# iorx65n register map
Registers are 8-bit, access not given, no defined reset value unless marked. A register's access mark holds for its fields unless they carry their own. Addresses are absolute; registers are grouped by the start of their names; [hi:lo] are bit positions; {n}, {i} and the like mark numbered series; 'fields as' and 'values as' point back to an identical list.

## SFR (part 2 of 7)
0x80000 SYSTEM 16-bit
  [0] MDMONR.MD
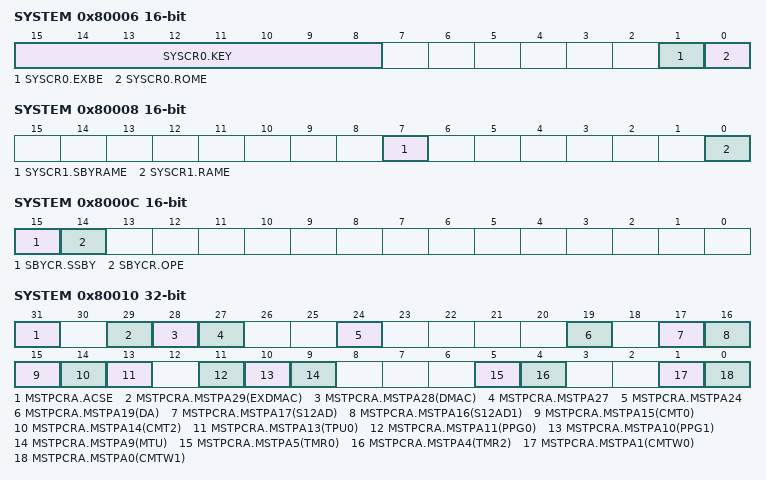
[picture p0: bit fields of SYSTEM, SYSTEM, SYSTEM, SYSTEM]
0x80006 SYSTEM 16-bit
  [15:8] SYSCR0.KEY, [1] SYSCR0.EXBE, [0] SYSCR0.ROME
0x80008 SYSTEM 16-bit
  [7] SYSCR1.SBYRAME, [0] SYSCR1.RAME
0x8000C SYSTEM 16-bit
  [15] SBYCR.SSBY, [14] SBYCR.OPE
0x80010 SYSTEM 32-bit
  [31] MSTPCRA.ACSE, [29] MSTPCRA.MSTPA29(EXDMAC), [28] MSTPCRA.MSTPA28(DMAC), [27] MSTPCRA.MSTPA27, [24] MSTPCRA.MSTPA24, [19] MSTPCRA.MSTPA19(DA), [17] MSTPCRA.MSTPA17(S12AD), [16] MSTPCRA.MSTPA16(S12AD1), [15] MSTPCRA.MSTPA15(CMT0), [14] MSTPCRA.MSTPA14(CMT2), [13] MSTPCRA.MSTPA13(TPU0), [11] MSTPCRA.MSTPA11(PPG0), [10] MSTPCRA.MSTPA10(PPG1), [9] MSTPCRA.MSTPA9(MTU), [5] MSTPCRA.MSTPA5(TMR0), [4] MSTPCRA.MSTPA4(TMR2), [1] MSTPCRA.MSTPA1(CMTW0), [0] MSTPCRA.MSTPA0(CMTW1)
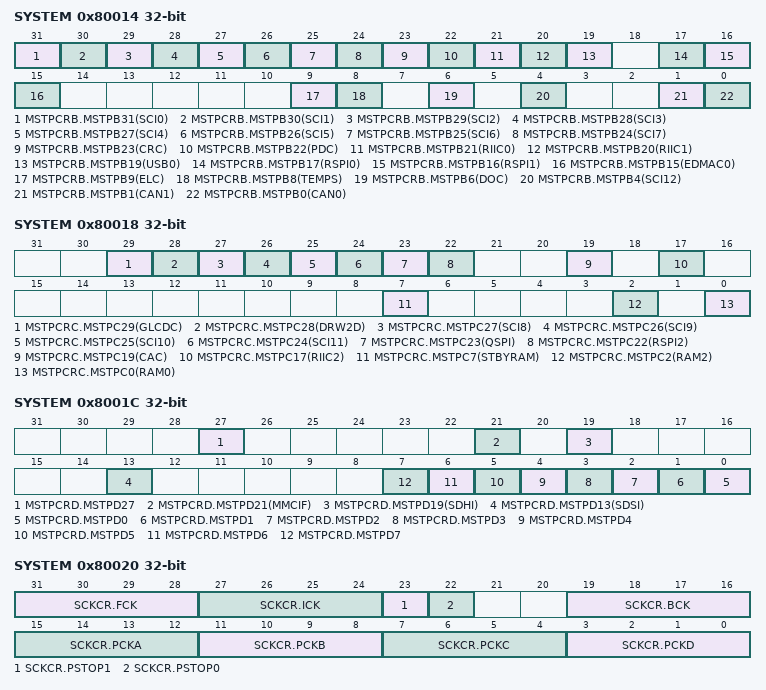
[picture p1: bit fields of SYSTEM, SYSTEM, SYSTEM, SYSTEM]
0x80014 SYSTEM 32-bit
  [31] MSTPCRB.MSTPB31(SCI0), [30] MSTPCRB.MSTPB30(SCI1), [29] MSTPCRB.MSTPB29(SCI2), [28] MSTPCRB.MSTPB28(SCI3), [27] MSTPCRB.MSTPB27(SCI4), [26] MSTPCRB.MSTPB26(SCI5), [25] MSTPCRB.MSTPB25(SCI6), [24] MSTPCRB.MSTPB24(SCI7), [23] MSTPCRB.MSTPB23(CRC), [22] MSTPCRB.MSTPB22(PDC), [21] MSTPCRB.MSTPB21(RIIC0), [20] MSTPCRB.MSTPB20(RIIC1), [19] MSTPCRB.MSTPB19(USB0), [17] MSTPCRB.MSTPB17(RSPI0), [16] MSTPCRB.MSTPB16(RSPI1), [15] MSTPCRB.MSTPB15(EDMAC0), [9] MSTPCRB.MSTPB9(ELC), [8] MSTPCRB.MSTPB8(TEMPS), [6] MSTPCRB.MSTPB6(DOC), [4] MSTPCRB.MSTPB4(SCI12), [1] MSTPCRB.MSTPB1(CAN1), [0] MSTPCRB.MSTPB0(CAN0)
0x80018 SYSTEM 32-bit
  [29] MSTPCRC.MSTPC29(GLCDC), [28] MSTPCRC.MSTPC28(DRW2D), [27] MSTPCRC.MSTPC27(SCI8), [26] MSTPCRC.MSTPC26(SCI9), [25] MSTPCRC.MSTPC25(SCI10), [24] MSTPCRC.MSTPC24(SCI11), [23] MSTPCRC.MSTPC23(QSPI), [22] MSTPCRC.MSTPC22(RSPI2), [19] MSTPCRC.MSTPC19(CAC), [17] MSTPCRC.MSTPC17(RIIC2), [7] MSTPCRC.MSTPC7(STBYRAM), [2] MSTPCRC.MSTPC2(RAM2), [0] MSTPCRC.MSTPC0(RAM0)
0x8001C SYSTEM 32-bit
  [27] MSTPCRD.MSTPD27, [21] MSTPCRD.MSTPD21(MMCIF), [19] MSTPCRD.MSTPD19(SDHI), [13] MSTPCRD.MSTPD13(SDSI), [n] MSTPCRD.MSTPD{n} (n=0..7)
0x80020 SYSTEM 32-bit
  [31:28] SCKCR.FCK, [27:24] SCKCR.ICK, [23] SCKCR.PSTOP1, [22] SCKCR.PSTOP0, [19:16] SCKCR.BCK, [15:12] SCKCR.PCKA, [11:8] SCKCR.PCKB, [7:4] SCKCR.PCKC, [3:0] SCKCR.PCKD
0x80024 SYSTEM 16-bit
  [7:4] SCKCR2.UCK
0x80026 SYSTEM 16-bit
  [10:8] SCKCR3.CKSEL
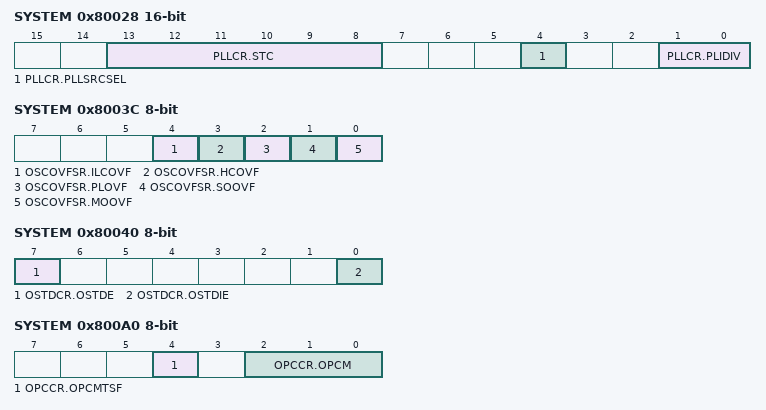
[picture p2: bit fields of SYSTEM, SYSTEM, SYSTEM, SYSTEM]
0x80028 SYSTEM 16-bit
  [13:8] PLLCR.STC, [4] PLLCR.PLLSRCSEL, [1:0] PLLCR.PLIDIV
0x8002A SYSTEM
  [0] PLLCR2.PLLEN
0x80030 SYSTEM
  [0] BCKCR.BCLKDIV
0x80032 SYSTEM
  [0] MOSCCR.MOSTP
0x80033 SYSTEM
  [0] SOSCCR.SOSTP
0x80034 SYSTEM
  [0] LOCOCR.LCSTP
0x80035 SYSTEM
  [0] ILOCOCR.ILCSTP
0x80036 SYSTEM
  [0] HOCOCR.HCSTP
0x80037 SYSTEM
  [1:0] HOCOCR2.HCFRQ
0x8003C SYSTEM
  [4] OSCOVFSR.ILCOVF, [3] OSCOVFSR.HCOVF, [2] OSCOVFSR.PLOVF, [1] OSCOVFSR.SOOVF, [0] OSCOVFSR.MOOVF
0x80040 SYSTEM
  [7] OSTDCR.OSTDE, [0] OSTDCR.OSTDIE
0x80041 SYSTEM
  [0] OSTDSR.OSTDF
0x800A0 SYSTEM
  [4] OPCCR.OPCMTSF, [2:0] OPCCR.OPCM
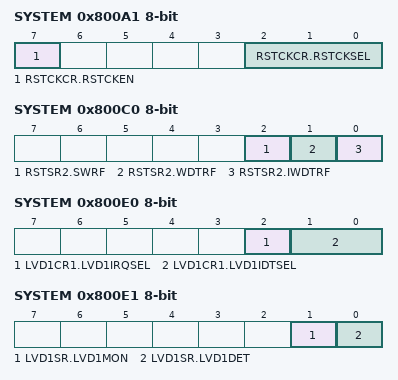
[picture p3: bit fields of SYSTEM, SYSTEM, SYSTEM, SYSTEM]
0x800A1 SYSTEM
  [7] RSTCKCR.RSTCKEN, [2:0] RSTCKCR.RSTCKSEL
0x800A2 SYSTEM
  [7:0] MOSCWTCR.MSTS
0x800A3 SYSTEM
  [7:0] SOSCWTCR.SSTS
0x800C0 SYSTEM
  [2] RSTSR2.SWRF, [1] RSTSR2.WDTRF, [0] RSTSR2.IWDTRF
0x800E0 SYSTEM
  [2] LVD1CR1.LVD1IRQSEL, [1:0] LVD1CR1.LVD1IDTSEL
0x800E1 SYSTEM
  [1] LVD1SR.LVD1MON, [0] LVD1SR.LVD1DET
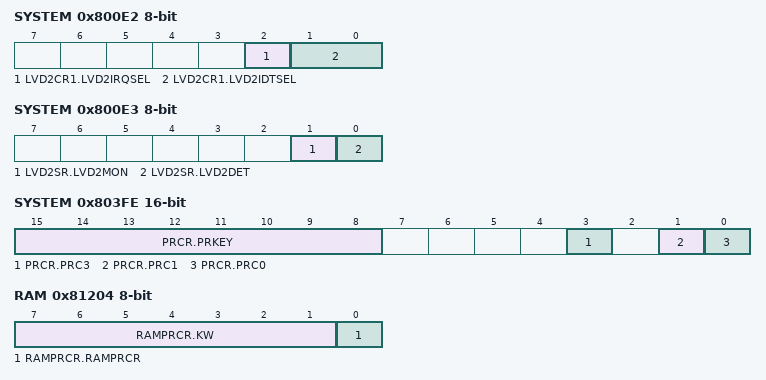
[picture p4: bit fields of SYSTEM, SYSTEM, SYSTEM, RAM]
0x800E2 SYSTEM
  [2] LVD2CR1.LVD2IRQSEL, [1:0] LVD2CR1.LVD2IDTSEL
0x800E3 SYSTEM
  [1] LVD2SR.LVD2MON, [0] LVD2SR.LVD2DET
0x803FE SYSTEM 16-bit
  [15:8] PRCR.PRKEY, [3] PRCR.PRC3, [1] PRCR.PRC1, [0] PRCR.PRC0
0x81000 FLASH 16-bit
  [0] ROMCE.ROMCEN
0x81004 FLASH 16-bit
  [0] ROMCIV.ROMCIV
0x8101C SYSTEM
  [1:0] ROMWT.ROMWT
0x81200 RAM
  [1:0] RAMMODE.RAMMODE
0x81201 RAM
  [0] RAMSTS.RAMERR
0x81204 RAM
  [7:1] RAMPRCR.KW, [0] RAMPRCR.RAMPRCR
0x81208 RAM 32-bit
  [18:3] RAMECAD.READ
0x81240 RAM
  [1:0] EXRAMMODE.EXRAMMODE
0x81241 RAM
  [0] EXRAMSTS.EXRAMERR
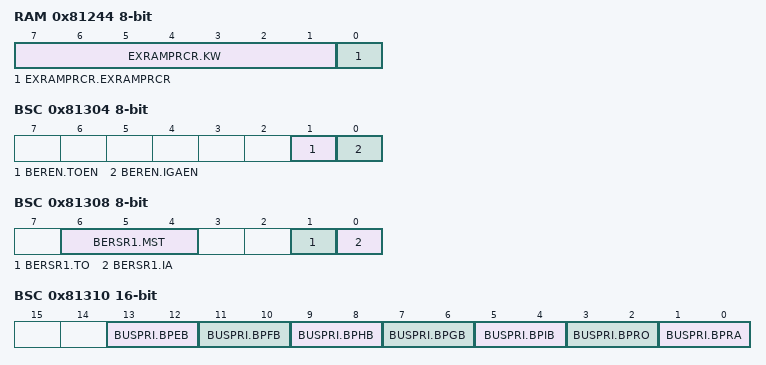
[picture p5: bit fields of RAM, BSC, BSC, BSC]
0x81244 RAM
  [7:1] EXRAMPRCR.KW, [0] EXRAMPRCR.EXRAMPRCR
0x81248 RAM 32-bit
  [18:3] EXRAMECAD.READ
0x81300 BSC
  [0] BERCLR.STSCLR
0x81304 BSC
  [1] BEREN.TOEN, [0] BEREN.IGAEN
0x81308 BSC
  [6:4] BERSR1.MST, [1] BERSR1.TO, [0] BERSR1.IA
0x8130A BSC 16-bit
  [15:3] BERSR2.ADDR
0x81310 BSC 16-bit
  [13:12] BUSPRI.BPEB, [11:10] BUSPRI.BPFB, [9:8] BUSPRI.BPHB, [7:6] BUSPRI.BPGB, [5:4] BUSPRI.BPIB, [3:2] BUSPRI.BPRO, [1:0] BUSPRI.BPRA
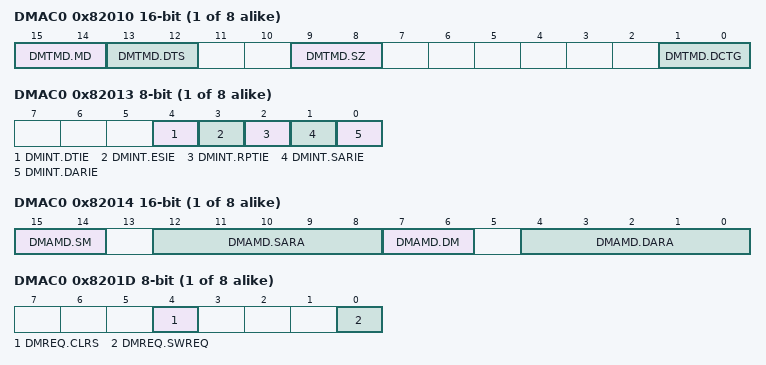
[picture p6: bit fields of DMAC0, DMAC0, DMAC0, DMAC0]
{0x82010+0x40*i} DMAC{i} 16-bit (i=0..7)
  [15:14] DMTMD.MD, [13:12] DMTMD.DTS, [9:8] DMTMD.SZ, [1:0] DMTMD.DCTG
{0x82013+0x40*i} DMAC{i} (i=0..7)
  [4] DMINT.DTIE, [3] DMINT.ESIE, [2] DMINT.RPTIE, [1] DMINT.SARIE, [0] DMINT.DARIE
{0x82014+0x40*i} DMAC{i} 16-bit (i=0..7)
  [15:14] DMAMD.SM, [12:8] DMAMD.SARA, [7:6] DMAMD.DM, [4:0] DMAMD.DARA
{0x8201C+0x40*i} DMAC{i} (i=0..7)
  [0] DMCNT.DTE
{0x8201D+0x40*i} DMAC{i} (i=0..7)
  [4] DMREQ.CLRS, [0] DMREQ.SWREQ
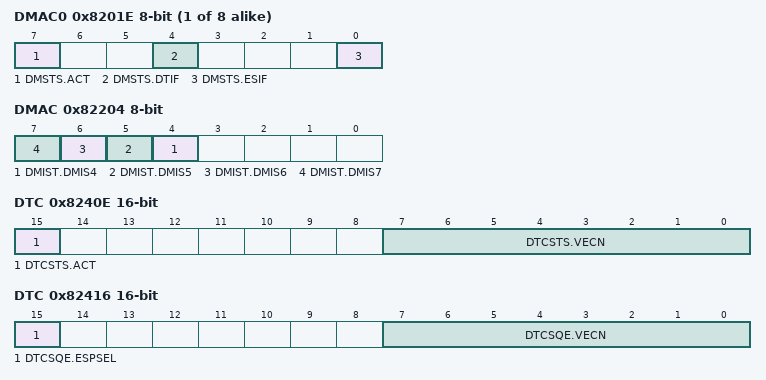
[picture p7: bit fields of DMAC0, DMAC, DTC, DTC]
{0x8201E+0x40*i} DMAC{i} (i=0..7)
  [7] DMSTS.ACT, [4] DMSTS.DTIF, [0] DMSTS.ESIF
{0x8201F+0x40*i} DMAC{i} (i=0..7)
  [0] DMCSL.DISEL
0x82200 DMAC
  [0] DMAST.DMST
0x82204 DMAC
  [n] DMIST.DMIS{n} (n=4..7)
0x82400 DTC
  [4] DTCCR.RRS
0x82408 DTC
  [0] DTCADMOD.SHORT
0x8240C DTC
  [0] DTCST.DTCST
0x8240E DTC 16-bit
  [15] DTCSTS.ACT, [7:0] DTCSTS.VECN
0x82414 DTC
  [0] DTCOR.SQTFRL
0x82416 DTC 16-bit
  [15] DTCSQE.ESPSEL, [7:0] DTCSQE.VECN
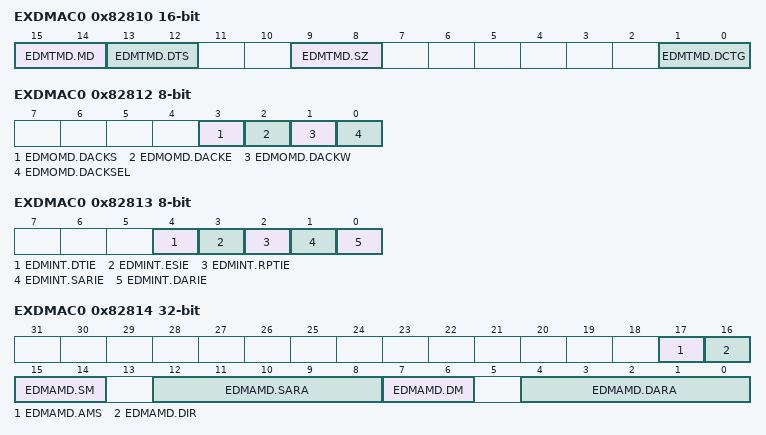
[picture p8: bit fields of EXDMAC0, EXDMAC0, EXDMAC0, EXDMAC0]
0x82810 EXDMAC0 16-bit
  [15:14] EDMTMD.MD, [13:12] EDMTMD.DTS, [9:8] EDMTMD.SZ, [1:0] EDMTMD.DCTG
0x82812 EXDMAC0
  [3] EDMOMD.DACKS, [2] EDMOMD.DACKE, [1] EDMOMD.DACKW, [0] EDMOMD.DACKSEL
0x82813 EXDMAC0
  [4] EDMINT.DTIE, [3] EDMINT.ESIE, [2] EDMINT.RPTIE, [1] EDMINT.SARIE, [0] EDMINT.DARIE
0x82814 EXDMAC0 32-bit
  [17] EDMAMD.AMS, [16] EDMAMD.DIR, [15:14] EDMAMD.SM, [12:8] EDMAMD.SARA, [7:6] EDMAMD.DM, [4:0] EDMAMD.DARA
0x8281C EXDMAC0
  [0] EDMCNT.DTE
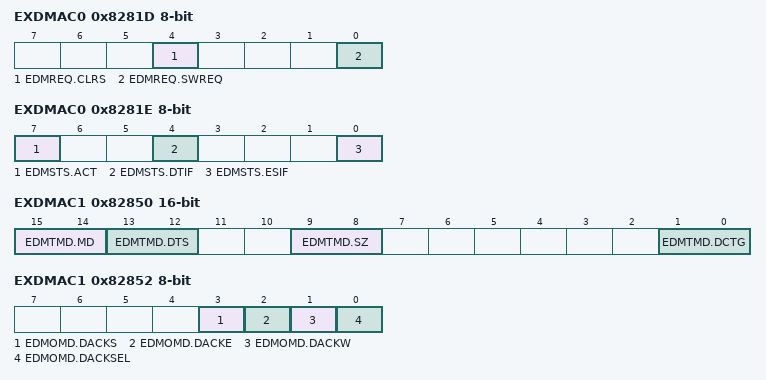
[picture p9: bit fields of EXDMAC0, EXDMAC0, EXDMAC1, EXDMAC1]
0x8281D EXDMAC0
  [4] EDMREQ.CLRS, [0] EDMREQ.SWREQ
0x8281E EXDMAC0
  [7] EDMSTS.ACT, [4] EDMSTS.DTIF, [0] EDMSTS.ESIF
0x82820 EXDMAC0
  [1:0] EDMRMD.DREQS
0x82821 EXDMAC0
  [0] EDMERF.EREQ
0x82822 EXDMAC0
  [0] EDMPRF.PREQ
0x82850 EXDMAC1 16-bit
  fields as EXDMAC0
0x82852 EXDMAC1
  [3] EDMOMD.DACKS, [2] EDMOMD.DACKE, [1] EDMOMD.DACKW, [0] EDMOMD.DACKSEL
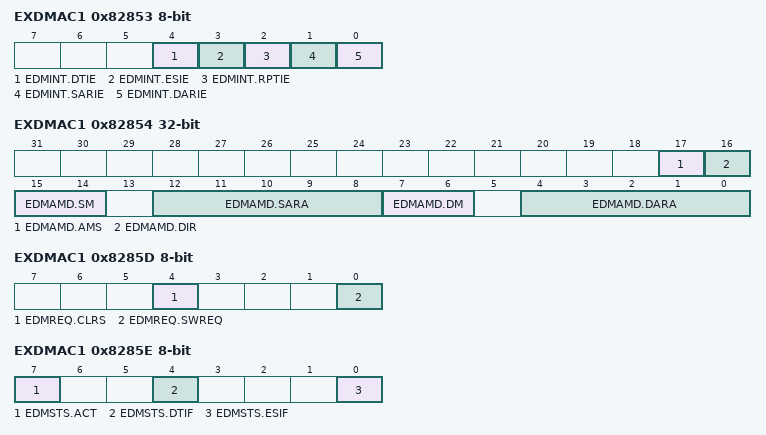
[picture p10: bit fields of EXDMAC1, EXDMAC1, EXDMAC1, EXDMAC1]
0x82853 EXDMAC1
  [4] EDMINT.DTIE, [3] EDMINT.ESIE, [2] EDMINT.RPTIE, [1] EDMINT.SARIE, [0] EDMINT.DARIE
0x82854 EXDMAC1 32-bit
  [17] EDMAMD.AMS, [16] EDMAMD.DIR, [15:14] EDMAMD.SM, [12:8] EDMAMD.SARA, [7:6] EDMAMD.DM, [4:0] EDMAMD.DARA
0x8285C EXDMAC1
  [0] EDMCNT.DTE
0x8285D EXDMAC1
  [4] EDMREQ.CLRS, [0] EDMREQ.SWREQ
0x8285E EXDMAC1
  [7] EDMSTS.ACT, [4] EDMSTS.DTIF, [0] EDMSTS.ESIF
0x82860 EXDMAC1
  [1:0] EDMRMD.DREQS
0x82861 EXDMAC1
  [0] EDMERF.EREQ
0x82862 EXDMAC1
  [0] EDMPRF.PREQ
0x82A00 EXDMAC
  [0] EDMAST.DMST
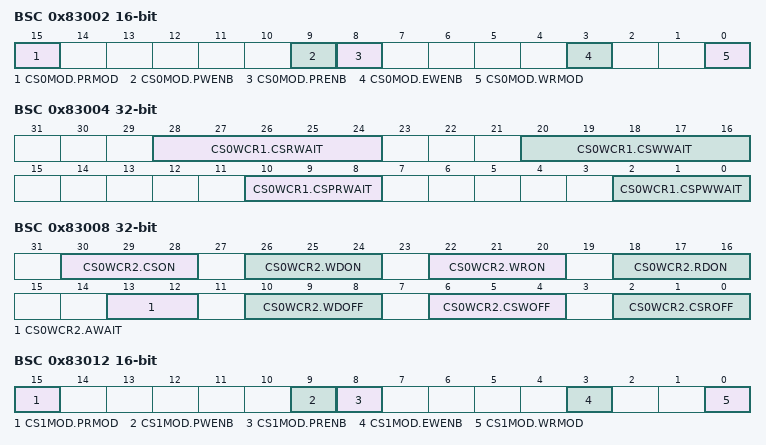
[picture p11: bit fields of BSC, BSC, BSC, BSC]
0x83002 BSC 16-bit
  [15] CS0MOD.PRMOD, [9] CS0MOD.PWENB, [8] CS0MOD.PRENB, [3] CS0MOD.EWENB, [0] CS0MOD.WRMOD
0x83004 BSC 32-bit
  [28:24] CS0WCR1.CSRWAIT, [20:16] CS0WCR1.CSWWAIT, [10:8] CS0WCR1.CSPRWAIT, [2:0] CS0WCR1.CSPWWAIT
0x83008 BSC 32-bit
  [30:28] CS0WCR2.CSON, [26:24] CS0WCR2.WDON, [22:20] CS0WCR2.WRON, [18:16] CS0WCR2.RDON, [13:12] CS0WCR2.AWAIT, [10:8] CS0WCR2.WDOFF, [6:4] CS0WCR2.CSWOFF, [2:0] CS0WCR2.CSROFF
0x83012 BSC 16-bit
  [15] CS1MOD.PRMOD, [9] CS1MOD.PWENB, [8] CS1MOD.PRENB, [3] CS1MOD.EWENB, [0] CS1MOD.WRMOD
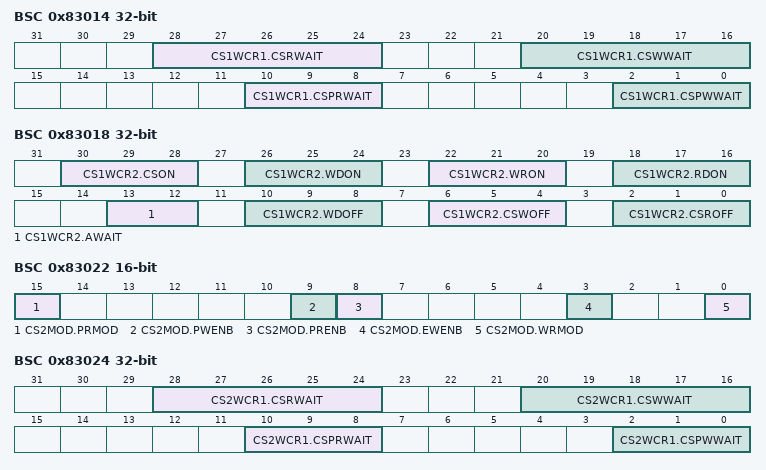
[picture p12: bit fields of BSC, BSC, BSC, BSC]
0x83014 BSC 32-bit
  [28:24] CS1WCR1.CSRWAIT, [20:16] CS1WCR1.CSWWAIT, [10:8] CS1WCR1.CSPRWAIT, [2:0] CS1WCR1.CSPWWAIT
0x83018 BSC 32-bit
  [30:28] CS1WCR2.CSON, [26:24] CS1WCR2.WDON, [22:20] CS1WCR2.WRON, [18:16] CS1WCR2.RDON, [13:12] CS1WCR2.AWAIT, [10:8] CS1WCR2.WDOFF, [6:4] CS1WCR2.CSWOFF, [2:0] CS1WCR2.CSROFF
0x83022 BSC 16-bit
  [15] CS2MOD.PRMOD, [9] CS2MOD.PWENB, [8] CS2MOD.PRENB, [3] CS2MOD.EWENB, [0] CS2MOD.WRMOD
0x83024 BSC 32-bit
  [28:24] CS2WCR1.CSRWAIT, [20:16] CS2WCR1.CSWWAIT, [10:8] CS2WCR1.CSPRWAIT, [2:0] CS2WCR1.CSPWWAIT
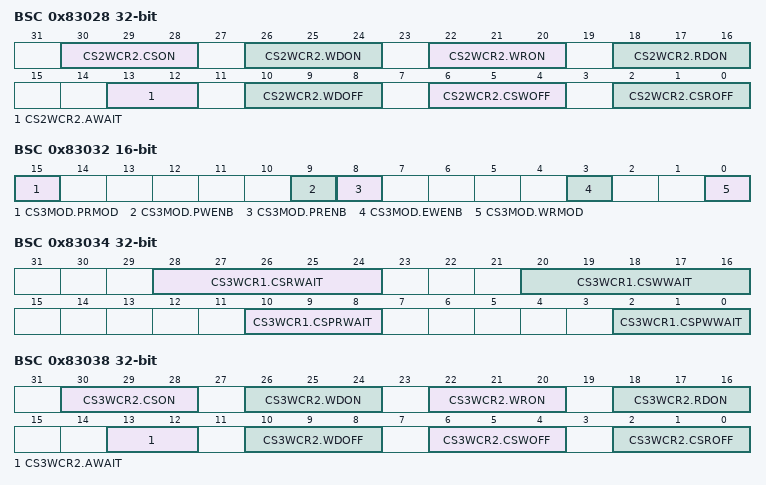
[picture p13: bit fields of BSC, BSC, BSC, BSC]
0x83028 BSC 32-bit
  [30:28] CS2WCR2.CSON, [26:24] CS2WCR2.WDON, [22:20] CS2WCR2.WRON, [18:16] CS2WCR2.RDON, [13:12] CS2WCR2.AWAIT, [10:8] CS2WCR2.WDOFF, [6:4] CS2WCR2.CSWOFF, [2:0] CS2WCR2.CSROFF
0x83032 BSC 16-bit
  [15] CS3MOD.PRMOD, [9] CS3MOD.PWENB, [8] CS3MOD.PRENB, [3] CS3MOD.EWENB, [0] CS3MOD.WRMOD
0x83034 BSC 32-bit
  [28:24] CS3WCR1.CSRWAIT, [20:16] CS3WCR1.CSWWAIT, [10:8] CS3WCR1.CSPRWAIT, [2:0] CS3WCR1.CSPWWAIT
0x83038 BSC 32-bit
  [30:28] CS3WCR2.CSON, [26:24] CS3WCR2.WDON, [22:20] CS3WCR2.WRON, [18:16] CS3WCR2.RDON, [13:12] CS3WCR2.AWAIT, [10:8] CS3WCR2.WDOFF, [6:4] CS3WCR2.CSWOFF, [2:0] CS3WCR2.CSROFF
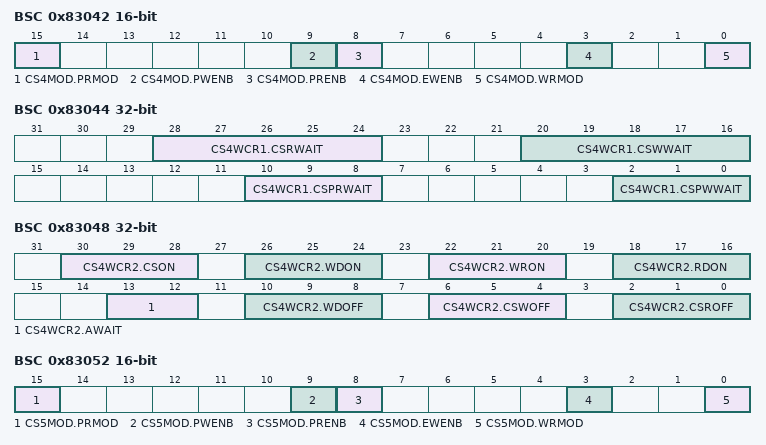
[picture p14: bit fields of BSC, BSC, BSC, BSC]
0x83042 BSC 16-bit
  [15] CS4MOD.PRMOD, [9] CS4MOD.PWENB, [8] CS4MOD.PRENB, [3] CS4MOD.EWENB, [0] CS4MOD.WRMOD
0x83044 BSC 32-bit
  [28:24] CS4WCR1.CSRWAIT, [20:16] CS4WCR1.CSWWAIT, [10:8] CS4WCR1.CSPRWAIT, [2:0] CS4WCR1.CSPWWAIT
0x83048 BSC 32-bit
  [30:28] CS4WCR2.CSON, [26:24] CS4WCR2.WDON, [22:20] CS4WCR2.WRON, [18:16] CS4WCR2.RDON, [13:12] CS4WCR2.AWAIT, [10:8] CS4WCR2.WDOFF, [6:4] CS4WCR2.CSWOFF, [2:0] CS4WCR2.CSROFF
0x83052 BSC 16-bit
  [15] CS5MOD.PRMOD, [9] CS5MOD.PWENB, [8] CS5MOD.PRENB, [3] CS5MOD.EWENB, [0] CS5MOD.WRMOD
0x83054 BSC 32-bit
  [28:24] CS5WCR1.CSRWAIT, [20:16] CS5WCR1.CSWWAIT, [10:8] CS5WCR1.CSPRWAIT, [2:0] CS5WCR1.CSPWWAIT
0x83058 BSC 32-bit
  [30:28] CS5WCR2.CSON, [26:24] CS5WCR2.WDON, [22:20] CS5WCR2.WRON, [18:16] CS5WCR2.RDON, [13:12] CS5WCR2.AWAIT, [10:8] CS5WCR2.WDOFF, [6:4] CS5WCR2.CSWOFF, [2:0] CS5WCR2.CSROFF
0x83062 BSC 16-bit
  [15] CS6MOD.PRMOD, [9] CS6MOD.PWENB, [8] CS6MOD.PRENB, [3] CS6MOD.EWENB, [0] CS6MOD.WRMOD
0x83064 BSC 32-bit
  [28:24] CS6WCR1.CSRWAIT, [20:16] CS6WCR1.CSWWAIT, [10:8] CS6WCR1.CSPRWAIT, [2:0] CS6WCR1.CSPWWAIT
0x83068 BSC 32-bit
  [30:28] CS6WCR2.CSON, [26:24] CS6WCR2.WDON, [22:20] CS6WCR2.WRON, [18:16] CS6WCR2.RDON, [13:12] CS6WCR2.AWAIT, [10:8] CS6WCR2.WDOFF, [6:4] CS6WCR2.CSWOFF, [2:0] CS6WCR2.CSROFF
0x83072 BSC 16-bit
  [15] CS7MOD.PRMOD, [9] CS7MOD.PWENB, [8] CS7MOD.PRENB, [3] CS7MOD.EWENB, [0] CS7MOD.WRMOD
0x83074 BSC 32-bit
  [28:24] CS7WCR1.CSRWAIT, [20:16] CS7WCR1.CSWWAIT, [10:8] CS7WCR1.CSPRWAIT, [2:0] CS7WCR1.CSPWWAIT
0x83078 BSC 32-bit
  [30:28] CS7WCR2.CSON, [26:24] CS7WCR2.WDON, [22:20] CS7WCR2.WRON, [18:16] CS7WCR2.RDON, [13:12] CS7WCR2.AWAIT, [10:8] CS7WCR2.WDOFF, [6:4] CS7WCR2.CSWOFF, [2:0] CS7WCR2.CSROFF
0x83802 BSC 16-bit
  [12] CS0CR.MPXEN, [8] CS0CR.EMODE, [5:4] CS0CR.BSIZE, [0] CS0CR.EXENB
0x8380A BSC 16-bit
  [11:8] CS0REC.WRCV, [3:0] CS0REC.RRCV
0x83812 BSC 16-bit
  [12] CS1CR.MPXEN, [8] CS1CR.EMODE, [5:4] CS1CR.BSIZE, [0] CS1CR.EXENB
0x8381A BSC 16-bit
  [11:8] CS1REC.WRCV, [3:0] CS1REC.RRCV
0x83822 BSC 16-bit
  [12] CS2CR.MPXEN, [8] CS2CR.EMODE, [5:4] CS2CR.BSIZE, [0] CS2CR.EXENB
0x8382A BSC 16-bit
  [11:8] CS2REC.WRCV, [3:0] CS2REC.RRCV
0x83832 BSC 16-bit
  [12] CS3CR.MPXEN, [8] CS3CR.EMODE, [5:4] CS3CR.BSIZE, [0] CS3CR.EXENB
0x8383A BSC 16-bit
  [11:8] CS3REC.WRCV, [3:0] CS3REC.RRCV
0x83842 BSC 16-bit
  [12] CS4CR.MPXEN, [8] CS4CR.EMODE, [5:4] CS4CR.BSIZE, [0] CS4CR.EXENB
0x8384A BSC 16-bit
  [11:8] CS4REC.WRCV, [3:0] CS4REC.RRCV
0x83852 BSC 16-bit
  [12] CS5CR.MPXEN, [8] CS5CR.EMODE, [5:4] CS5CR.BSIZE, [0] CS5CR.EXENB
0x8385A BSC 16-bit
  [11:8] CS5REC.WRCV, [3:0] CS5REC.RRCV
0x83862 BSC 16-bit
  [12] CS6CR.MPXEN, [8] CS6CR.EMODE, [5:4] CS6CR.BSIZE, [0] CS6CR.EXENB
0x8386A BSC 16-bit
  [11:8] CS6REC.WRCV, [3:0] CS6REC.RRCV
0x83872 BSC 16-bit
  [12] CS7CR.MPXEN, [8] CS7CR.EMODE, [5:4] CS7CR.BSIZE, [0] CS7CR.EXENB
0x8387A BSC 16-bit
  [11:8] CS7REC.WRCV, [3:0] CS7REC.RRCV
0x83880 BSC 16-bit
  [n+8] CSRECEN.RCVENM{n} (n=0..7), [n] CSRECEN.RCVEN{n} (n=0..7)
0x83C00 BSC
  [5:4] SDCCR.BSIZE, [0] SDCCR.EXENB
0x83C01 BSC
  [0] SDCMOD.EMODE
0x83C02 BSC
  [0] SDAMOD.BE
0x83C10 BSC
  [0] SDSELF.SFEN
0x83C14 BSC 16-bit
  [15:12] SDRFCR.REFW, [11:0] SDRFCR.RFC
0x83C16 BSC
  [0] SDRFEN.RFEN
0x83C20 BSC
  [0] SDICR.INIRQ
0x83C24 BSC 16-bit
  [10:8] SDIR.PRC, [7:4] SDIR.ARFC, [3:0] SDIR.ARFI
0x83C40 BSC
  [1:0] SDADR.MXC
0x83C44 BSC 32-bit
  [18:16] SDTR.RAS, [13:12] SDTR.RCD, [11:9] SDTR.RP, [8] SDTR.WR, [2:0] SDTR.CL
0x83C48 BSC 16-bit
  [14:0] SDMOD.MR
0x83C50 BSC
  [4] SDSR.SRFST, [3] SDSR.INIST, [0] SDSR.MRSST
0x86400 MPU 32-bit
  [31:4] RSPAGE0.RSPN
0x86404 MPU 32-bit
  [31:4] REPAGE0.REPN, [3:1] REPAGE0.UAC, [0] REPAGE0.V
0x86408 MPU 32-bit
  [31:4] RSPAGE1.RSPN
0x8640C MPU 32-bit
  [31:4] REPAGE1.REPN, [3:1] REPAGE1.UAC, [0] REPAGE1.V
0x86410 MPU 32-bit
  [31:4] RSPAGE2.RSPN
0x86414 MPU 32-bit
  [31:4] REPAGE2.REPN, [3:1] REPAGE2.UAC, [0] REPAGE2.V
0x86418 MPU 32-bit
  [31:4] RSPAGE3.RSPN
0x8641C MPU 32-bit
  [31:4] REPAGE3.REPN, [3:1] REPAGE3.UAC, [0] REPAGE3.V
0x86420 MPU 32-bit
  [31:4] RSPAGE4.RSPN
0x86424 MPU 32-bit
  [31:4] REPAGE4.REPN, [3:1] REPAGE4.UAC, [0] REPAGE4.V
0x86428 MPU 32-bit
  [31:4] RSPAGE5.RSPN
0x8642C MPU 32-bit
  [31:4] REPAGE5.REPN, [3:1] REPAGE5.UAC, [0] REPAGE5.V
0x86430 MPU 32-bit
  [31:4] RSPAGE6.RSPN
0x86434 MPU 32-bit
  [31:4] REPAGE6.REPN, [3:1] REPAGE6.UAC, [0] REPAGE6.V
0x86438 MPU 32-bit
  [31:4] RSPAGE7.RSPN
0x8643C MPU 32-bit
  [31:4] REPAGE7.REPN, [3:1] REPAGE7.UAC, [0] REPAGE7.V
0x86500 MPU 32-bit
  [0] MPEN.MPEN
0x86504 MPU 32-bit
  [3:1] MPBAC.UBAC
0x86508 MPU 32-bit
  [0] MPECLR.CLR
0x8650C MPU 32-bit
  [2] MPESTS.DRW, [1] MPESTS.DMPER, [0] MPESTS.IMPER
0x86514 MPU 32-bit
  [31:0] MPDEA.DEA
0x86520 MPU 32-bit
  [31:0] MPSA.SA
0x86524 MPU 16-bit
  [0] MPOPS.S
0x86526 MPU 16-bit
  [0] MPOPI.INV
0x86528 MPU 32-bit
  [23:16] MHITI.HITI, [3:1] MHITI.UHACI
0x8652C MPU 32-bit
  [23:16] MHITD.HITD, [3:1] MHITD.UHACD
0x87000 ICU
  [0] IR[0].IR
0x87001 ICU
  [0] IR[1].IR
0x87002 ICU
  [0] IR[2].IR
0x87003 ICU
  [0] IR[3].IR
0x87004 ICU
  [0] IR[4].IR
0x87005 ICU
  [0] IR[5].IR
0x87006 ICU
  [0] IR[6].IR
0x87007 ICU
  [0] IR[7].IR
0x87008 ICU
  [0] IR[8].IR
0x87009 ICU
  [0] IR[9].IR
0x8700A ICU
  [0] IR[10].IR
0x8700B ICU
  [0] IR[11].IR
0x8700C ICU
  [0] IR[12].IR
0x8700D ICU
  [0] IR[13].IR
0x8700E ICU
  [0] IR[14].IR
0x8700F ICU
  [0] IR[15].IR
0x87010 ICU
  [0] IR[16](BSC,BUSERR).IR
0x87011 ICU
  [0] IR[17].IR
0x87012 ICU
  [0] IR[18](RAM,RAMERR).IR
0x87013 ICU
  [0] IR[19].IR
0x87014 ICU
  [0] IR[20].IR
0x87015 ICU
  [0] IR[21](FCU,FIFERR).IR
0x87016 ICU
  [0] IR[22].IR
0x87017 ICU
  [0] IR[23](FCU,FRDYI).IR
0x87018 ICU
  [0] IR[24].IR
0x87019 ICU
  [0] IR[25].IR
0x8701A ICU
  [0] IR[26](ICU,SWINT2).IR
0x8701B ICU
  [0] IR[27](ICU,SWINT).IR
0x8701C ICU
  [0] IR[28](CMT0,CMI0).IR
0x8701D ICU
  [0] IR[29](CMT1,CMI1).IR
0x8701E ICU
  [0] IR[30](CMTW0,CMWI0).IR
0x8701F ICU
  [0] IR[31](CMTW1,CMWI1).IR
0x87020 ICU
  [0] IR[32].IR
0x87021 ICU
  [0] IR[33].IR
0x87022 ICU
  [0] IR[34](USB0,D0FIFO0).IR
0x87023 ICU
  [0] IR[35](USB0,D1FIFO0).IR
0x87024 ICU
  [0] IR[36].IR
0x87025 ICU
  [0] IR[37].IR
0x87026 ICU
  [0] IR[38](RSPI0,SPRI0).IR
0x87027 ICU
  [0] IR[39](RSPI0,SPTI0).IR
0x87028 ICU
  [0] IR[40](RSPI1,SPRI1).IR
0x87029 ICU
  [0] IR[41](RSPI1,SPTI1).IR
0x8702A ICU
  [0] IR[42](QSPI,SPRI).IR
0x8702B ICU
  [0] IR[43](QSPI,SPTI).IR
0x8702C ICU
  [0] IR[44](SDHI,SBFAI).IR
0x8702D ICU
  [0] IR[45](MMCIF,MBFAI).IR
0x8702E ICU
  [0] IR[46].IR
0x8702F ICU
  [0] IR[47].IR
0x87030 ICU
  [0] IR[48].IR
0x87031 ICU
  [0] IR[49].IR
0x87032 ICU
  [0] IR[50](RIIC1,RXI1).IR
0x87033 ICU
  [0] IR[51](RIIC1,TXI1).IR
0x87034 ICU
  [0] IR[52](RIIC0,RXI0).IR
0x87035 ICU
  [0] IR[53](RIIC0,TXI0).IR
0x87036 ICU
  [0] IR[54](RIIC2,RXI2).IR
0x87037 ICU
  [0] IR[55](RIIC2,TXI2).IR
0x87038 ICU
  [0] IR[56].IR
0x87039 ICU
  [0] IR[57].IR
0x8703A ICU
  [0] IR[58](SCI0,RXI0).IR
0x8703B ICU
  [0] IR[59](SCI0,TXI0).IR
0x8703C ICU
  [0] IR[60](SCI1,RXI1).IR
0x8703D ICU
  [0] IR[61](SCI1,TXI1).IR
0x8703E ICU
  [0] IR[62](SCI2,RXI2).IR
0x8703F ICU
  [0] IR[63](SCI2,TXI2).IR
0x87040 ICU
  [0] IR[64](ICU,IRQ0).IR
0x87041 ICU
  [0] IR[65](ICU,IRQ1).IR
0x87042 ICU
  [0] IR[66](ICU,IRQ2).IR
0x87043 ICU
  [0] IR[67](ICU,IRQ3).IR
0x87044 ICU
  [0] IR[68](ICU,IRQ4).IR
0x87045 ICU
  [0] IR[69](ICU,IRQ5).IR
0x87046 ICU
  [0] IR[70](ICU,IRQ6).IR
0x87047 ICU
  [0] IR[71](ICU,IRQ7).IR
0x87048 ICU
  [0] IR[72](ICU,IRQ8).IR
0x87049 ICU
  [0] IR[73](ICU,IRQ9).IR
0x8704A ICU
  [0] IR[74](ICU,IRQ10).IR
0x8704B ICU
  [0] IR[75](ICU,IRQ11).IR
0x8704C ICU
  [0] IR[76](ICU,IRQ12).IR
0x8704D ICU
  [0] IR[77](ICU,IRQ13).IR
0x8704E ICU
  [0] IR[78](ICU,IRQ14).IR
0x8704F ICU
  [0] IR[79](ICU,IRQ15).IR
0x87050 ICU
  [0] IR[80](SCI3,RXI3).IR
0x87051 ICU
  [0] IR[81](SCI3,TXI3).IR
0x87052 ICU
  [0] IR[82](SCI4,RXI4).IR
0x87053 ICU
  [0] IR[83](SCI4,TXI4).IR
0x87054 ICU
  [0] IR[84](SCI5,RXI5).IR
0x87055 ICU
  [0] IR[85](SCI5,TXI5).IR
0x87056 ICU
  [0] IR[86](SCI6,RXI6).IR
0x87057 ICU
  [0] IR[87](SCI6,TXI6).IR
0x87058 ICU
  [0] IR[88](LVD1,LVD1).IR
0x87059 ICU
  [0] IR[89](LVD2,LVD2).IR
0x8705A ICU
  [0] IR[90](USB0,USBR0).IR
0x8705B ICU
  [0] IR[91].IR
0x8705C ICU
  [0] IR[92](RTC,ALM).IR
0x8705D ICU
  [0] IR[93](RTC,PRD).IR
0x8705E ICU
  [0] IR[94].IR
0x8705F ICU
  [0] IR[95](IWDT,IWUNI).IR
0x87060 ICU
  [0] IR[96](WDT,WUNI).IR
0x87061 ICU
  [0] IR[97](PDC,PCDFI).IR
0x87062 ICU
  [0] IR[98](SCI7,RXI7).IR
0x87063 ICU
  [0] IR[99](SCI7,TXI7).IR
0x87064 ICU
  [0] IR[100](SCI8,RXI8).IR
0x87065 ICU
  [0] IR[101](SCI8,TXI8).IR
0x87066 ICU
  [0] IR[102](SCI9,RXI9).IR
0x87067 ICU
  [0] IR[103](SCI9,TXI9).IR
0x87068 ICU
  [0] IR[104](SCI10,RXI10).IR
0x87069 ICU
  [0] IR[105](SCI10,TXI10).IR
0x8706A ICU
  [0] IR[106](ICU,GROUPBE0).IR
0x8706B ICU
  [0] IR[107](ICU,GROUPBL2).IR
0x8706C ICU
  [0] IR[108](RSPI2,SPRI2).IR
0x8706D ICU
  [0] IR[109](RSPI2,SPTI2).IR
0x8706E ICU
  [0] IR[110](ICU,GROUPBL0).IR
0x8706F ICU
  [0] IR[111](ICU,GROUPBL1).IR
0x87070 ICU
  [0] IR[112](ICU,GROUPAL0).IR
0x87071 ICU
  [0] IR[113](ICU,GROUPAL1).IR
0x87072 ICU
  [0] IR[114](SCI11,RXI11).IR
0x87073 ICU
  [0] IR[115](SCI11,TXI11).IR
0x87074 ICU
  [0] IR[116](SCI12,RXI12).IR
0x87075 ICU
  [0] IR[117](SCI12,TXI12).IR
0x87076 ICU
  [0] IR[118].IR
0x87077 ICU
  [0] IR[119].IR
0x87078 ICU
  [0] IR[120](DMAC,DMAC0I).IR
0x87079 ICU
  [0] IR[121](DMAC,DMAC1I).IR
0x8707A ICU
  [0] IR[122](DMAC,DMAC2I).IR
0x8707B ICU
  [0] IR[123](DMAC,DMAC3I).IR
0x8707C ICU
  [0] IR[124](DMAC,DMAC74I).IR
0x8707D ICU
  [0] IR[125](OST,OSTDI).IR
0x8707E ICU
  [0] IR[126](EXDMAC,EXDMAC0I).IR
0x8707F ICU
  [0] IR[127](EXDMAC,EXDMAC1I).IR
0x87080 ICU
  [0] IR[128](PERIB,INTB128).IR
0x87081 ICU
  [0] IR[129](PERIB,INTB129).IR
0x87082 ICU
  [0] IR[130](PERIB,INTB130).IR
0x87083 ICU
  [0] IR[131](PERIB,INTB131).IR
0x87084 ICU
  [0] IR[132](PERIB,INTB132).IR
0x87085 ICU
  [0] IR[133](PERIB,INTB133).IR
0x87086 ICU
  [0] IR[134](PERIB,INTB134).IR
0x87087 ICU
  [0] IR[135](PERIB,INTB135).IR
0x87088 ICU
  [0] IR[136](PERIB,INTB136).IR
0x87089 ICU
  [0] IR[137](PERIB,INTB137).IR
0x8708A ICU
  [0] IR[138](PERIB,INTB138).IR
0x8708B ICU
  [0] IR[139](PERIB,INTB139).IR
0x8708C ICU
  [0] IR[140](PERIB,INTB140).IR
0x8708D ICU
  [0] IR[141](PERIB,INTB141).IR
0x8708E ICU
  [0] IR[142](PERIB,INTB142).IR
0x8708F ICU
  [0] IR[143](PERIB,INTB143).IR
0x87090 ICU
  [0] IR[144](PERIB,INTB144).IR
0x87091 ICU
  [0] IR[145](PERIB,INTB145).IR
0x87092 ICU
  [0] IR[146](PERIB,INTB146).IR
0x87093 ICU
  [0] IR[147](PERIB,INTB147).IR
0x87094 ICU
  [0] IR[148](PERIB,INTB148).IR
0x87095 ICU
  [0] IR[149](PERIB,INTB149).IR
0x87096 ICU
  [0] IR[150](PERIB,INTB150).IR
0x87097 ICU
  [0] IR[151](PERIB,INTB151).IR
0x87098 ICU
  [0] IR[152](PERIB,INTB152).IR
0x87099 ICU
  [0] IR[153](PERIB,INTB153).IR
0x8709A ICU
  [0] IR[154](PERIB,INTB154).IR
0x8709B ICU
  [0] IR[155](PERIB,INTB155).IR
0x8709C ICU
  [0] IR[156](PERIB,INTB156).IR
0x8709D ICU
  [0] IR[157](PERIB,INTB157).IR
0x8709E ICU
  [0] IR[158](PERIB,INTB158).IR
0x8709F ICU
  [0] IR[159](PERIB,INTB159).IR
0x870A0 ICU
  [0] IR[160](PERIB,INTB160).IR
0x870A1 ICU
  [0] IR[161](PERIB,INTB161).IR
0x870A2 ICU
  [0] IR[162](PERIB,INTB162).IR
0x870A3 ICU
  [0] IR[163](PERIB,INTB163).IR
0x870A4 ICU
  [0] IR[164](PERIB,INTB164).IR
0x870A5 ICU
  [0] IR[165](PERIB,INTB165).IR
0x870A6 ICU
  [0] IR[166](PERIB,INTB166).IR
0x870A7 ICU
  [0] IR[167](PERIB,INTB167).IR
0x870A8 ICU
  [0] IR[168](PERIB,INTB168).IR
0x870A9 ICU
  [0] IR[169](PERIB,INTB169).IR
0x870AA ICU
  [0] IR[170](PERIB,INTB170).IR
0x870AB ICU
  [0] IR[171](PERIB,INTB171).IR
0x870AC ICU
  [0] IR[172](PERIB,INTB172).IR
0x870AD ICU
  [0] IR[173](PERIB,INTB173).IR
0x870AE ICU
  [0] IR[174](PERIB,INTB174).IR
0x870AF ICU
  [0] IR[175](PERIB,INTB175).IR
0x870B0 ICU
  [0] IR[176](PERIB,INTB176).IR
0x870B1 ICU
  [0] IR[177](PERIB,INTB177).IR
0x870B2 ICU
  [0] IR[178](PERIB,INTB178).IR
0x870B3 ICU
  [0] IR[179](PERIB,INTB179).IR
0x870B4 ICU
  [0] IR[180](PERIB,INTB180).IR
0x870B5 ICU
  [0] IR[181](PERIB,INTB181).IR
0x870B6 ICU
  [0] IR[182](PERIB,INTB182).IR
0x870B7 ICU
  [0] IR[183](PERIB,INTB183).IR
0x870B8 ICU
  [0] IR[184](PERIB,INTB184).IR
0x870B9 ICU
  [0] IR[185](PERIB,INTB185).IR
0x870BA ICU
  [0] IR[186](PERIB,INTB186).IR
0x870BB ICU
  [0] IR[187](PERIB,INTB187).IR
0x870BC ICU
  [0] IR[188](PERIB,INTB188).IR
0x870BD ICU
  [0] IR[189](PERIB,INTB189).IR
0x870BE ICU
  [0] IR[190](PERIB,INTB190).IR
0x870BF ICU
  [0] IR[191](PERIB,INTB191).IR
0x870C0 ICU
  [0] IR[192](PERIB,INTB192).IR
0x870C1 ICU
  [0] IR[193](PERIB,INTB193).IR
0x870C2 ICU
  [0] IR[194](PERIB,INTB194).IR
0x870C3 ICU
  [0] IR[195](PERIB,INTB195).IR
0x870C4 ICU
  [0] IR[196](PERIB,INTB196).IR
0x870C5 ICU
  [0] IR[197](PERIB,INTB197).IR
0x870C6 ICU
  [0] IR[198](PERIB,INTB198).IR
0x870C7 ICU
  [0] IR[199](PERIB,INTB199).IR
0x870C8 ICU
  [0] IR[200](PERIB,INTB200).IR
0x870C9 ICU
  [0] IR[201](PERIB,INTB201).IR
0x870CA ICU
  [0] IR[202](PERIB,INTB202).IR
0x870CB ICU
  [0] IR[203](PERIB,INTB203).IR
0x870CC ICU
  [0] IR[204](PERIB,INTB204).IR
0x870CD ICU
  [0] IR[205](PERIB,INTB205).IR
0x870CE ICU
  [0] IR[206](PERIB,INTB206).IR
0x870CF ICU
  [0] IR[207](PERIB,INTB207).IR
0x870D0 ICU
  [0] IR[208](PERIA,INTA208).IR
0x870D1 ICU
  [0] IR[209](PERIA,INTA209).IR
0x870D2 ICU
  [0] IR[210](PERIA,INTA210).IR
0x870D3 ICU
  [0] IR[211](PERIA,INTA211).IR
0x870D4 ICU
  [0] IR[212](PERIA,INTA212).IR
0x870D5 ICU
  [0] IR[213](PERIA,INTA213).IR
0x870D6 ICU
  [0] IR[214](PERIA,INTA214).IR
0x870D7 ICU
  [0] IR[215](PERIA,INTA215).IR
0x870D8 ICU
  [0] IR[216](PERIA,INTA216).IR
0x870D9 ICU
  [0] IR[217](PERIA,INTA217).IR
0x870DA ICU
  [0] IR[218](PERIA,INTA218).IR
0x870DB ICU
  [0] IR[219](PERIA,INTA219).IR
0x870DC ICU
  [0] IR[220](PERIA,INTA220).IR
0x870DD ICU
  [0] IR[221](PERIA,INTA221).IR
0x870DE ICU
  [0] IR[222](PERIA,INTA222).IR
0x870DF ICU
  [0] IR[223](PERIA,INTA223).IR
0x870E0 ICU
  [0] IR[224](PERIA,INTA224).IR
0x870E1 ICU
  [0] IR[225](PERIA,INTA225).IR
0x870E2 ICU
  [0] IR[226](PERIA,INTA226).IR
0x870E3 ICU
  [0] IR[227](PERIA,INTA227).IR
0x870E4 ICU
  [0] IR[228](PERIA,INTA228).IR
0x870E5 ICU
  [0] IR[229](PERIA,INTA229).IR
0x870E6 ICU
  [0] IR[230](PERIA,INTA230).IR
0x870E7 ICU
  [0] IR[231](PERIA,INTA231).IR
0x870E8 ICU
  [0] IR[232](PERIA,INTA232).IR
0x870E9 ICU
  [0] IR[233](PERIA,INTA233).IR
0x870EA ICU
  [0] IR[234](PERIA,INTA234).IR
0x870EB ICU
  [0] IR[235](PERIA,INTA235).IR
0x870EC ICU
  [0] IR[236](PERIA,INTA236).IR
0x870ED ICU
  [0] IR[237](PERIA,INTA237).IR
0x870EE ICU
  [0] IR[238](PERIA,INTA238).IR
0x870EF ICU
  [0] IR[239](PERIA,INTA239).IR
0x870F0 ICU
  [0] IR[240](PERIA,INTA240).IR
0x870F1 ICU
  [0] IR[241](PERIA,INTA241).IR
0x870F2 ICU
  [0] IR[242](PERIA,INTA242).IR
0x870F3 ICU
  [0] IR[243](PERIA,INTA243).IR
0x870F4 ICU
  [0] IR[244](PERIA,INTA244).IR
0x870F5 ICU
  [0] IR[245](PERIA,INTA245).IR
0x870F6 ICU
  [0] IR[246](PERIA,INTA246).IR
0x870F7 ICU
  [0] IR[247](PERIA,INTA247).IR
0x870F8 ICU
  [0] IR[248](PERIA,INTA248).IR
0x870F9 ICU
  [0] IR[249](PERIA,INTA249).IR
0x870FA ICU
  [0] IR[250](PERIA,INTA250).IR
0x870FB ICU
  [0] IR[251](PERIA,INTA251).IR
0x870FC ICU
  [0] IR[252](PERIA,INTA252).IR
0x870FD ICU
  [0] IR[253](PERIA,INTA253).IR
0x870FE ICU
  [0] IR[254](PERIA,INTA254).IR
0x870FF ICU
  [0] IR[255](PERIA,INTA255).IR
0x87100 ICU
  [0] DTCER[0].DTCE
0x87101 ICU
  [0] DTCER[1].DTCE
0x87102 ICU
  [0] DTCER[2].DTCE
0x87103 ICU
  [0] DTCER[3].DTCE
0x87104 ICU
  [0] DTCER[4].DTCE
0x87105 ICU
  [0] DTCER[5].DTCE
0x87106 ICU
  [0] DTCER[6].DTCE
0x87107 ICU
  [0] DTCER[7].DTCE
0x87108 ICU
  [0] DTCER[8].DTCE
0x87109 ICU
  [0] DTCER[9].DTCE
0x8710A ICU
  [0] DTCER[10].DTCE
0x8710B ICU
  [0] DTCER[11].DTCE
0x8710C ICU
  [0] DTCER[12].DTCE
0x8710D ICU
  [0] DTCER[13].DTCE
0x8710E ICU
  [0] DTCER[14].DTCE
0x8710F ICU
  [0] DTCER[15].DTCE
0x87110 ICU
  [0] DTCER[16](BSC,BUSERR).DTCE
0x87111 ICU
  [0] DTCER[17].DTCE
0x87112 ICU
  [0] DTCER[18](RAM,RAMERR).DTCE
0x87113 ICU
  [0] DTCER[19].DTCE
0x87114 ICU
  [0] DTCER[20].DTCE
0x87115 ICU
  [0] DTCER[21](FCU,FIFERR).DTCE
0x87116 ICU
  [0] DTCER[22].DTCE
0x87117 ICU
  [0] DTCER[23](FCU,FRDYI).DTCE
0x87118 ICU
  [0] DTCER[24].DTCE
0x87119 ICU
  [0] DTCER[25].DTCE
0x8711A ICU
  [0] DTCER[26](ICU,SWINT2).DTCE
0x8711B ICU
  [0] DTCER[27](ICU,SWINT).DTCE
0x8711C ICU
  [0] DTCER[28](CMT0,CMI0).DTCE
0x8711D ICU
  [0] DTCER[29](CMT1,CMI1).DTCE
0x8711E ICU
  [0] DTCER[30](CMTW0,CMWI0).DTCE
0x8711F ICU
  [0] DTCER[31](CMTW1,CMWI1).DTCE
0x87120 ICU
  [0] DTCER[32].DTCE
0x87121 ICU
  [0] DTCER[33].DTCE
0x87122 ICU
  [0] DTCER[34](USB0,D0FIFO0).DTCE
0x87123 ICU
  [0] DTCER[35](USB0,D1FIFO0).DTCE
0x87124 ICU
  [0] DTCER[36].DTCE
0x87125 ICU
  [0] DTCER[37].DTCE
0x87126 ICU
  [0] DTCER[38](RSPI0,SPRI0).DTCE
0x87127 ICU
  [0] DTCER[39](RSPI0,SPTI0).DTCE
0x87128 ICU
  [0] DTCER[40](RSPI1,SPRI1).DTCE
0x87129 ICU
  [0] DTCER[41](RSPI1,SPTI1).DTCE
0x8712A ICU
  [0] DTCER[42](QSPI,SPRI).DTCE
0x8712B ICU
  [0] DTCER[43](QSPI,SPTI).DTCE
0x8712C ICU
  [0] DTCER[44](SDHI,SBFAI).DTCE
0x8712D ICU
  [0] DTCER[45](MMCIF,MBFAI).DTCE
0x8712E ICU
  [0] DTCER[46].DTCE
0x8712F ICU
  [0] DTCER[47].DTCE
0x87130 ICU
  [0] DTCER[48].DTCE
0x87131 ICU
  [0] DTCER[49].DTCE
0x87132 ICU
  [0] DTCER[50](RIIC1,RXI1).DTCE
0x87133 ICU
  [0] DTCER[51](RIIC1,TXI1).DTCE
0x87134 ICU
  [0] DTCER[52](RIIC0,RXI0).DTCE
0x87135 ICU
  [0] DTCER[53](RIIC0,TXI0).DTCE
0x87136 ICU
  [0] DTCER[54](RIIC2,RXI2).DTCE
0x87137 ICU
  [0] DTCER[55](RIIC2,TXI2).DTCE
0x87138 ICU
  [0] DTCER[56].DTCE
0x87139 ICU
  [0] DTCER[57].DTCE
0x8713A ICU
  [0] DTCER[58](SCI0,RXI0).DTCE
0x8713B ICU
  [0] DTCER[59](SCI0,TXI0).DTCE
0x8713C ICU
  [0] DTCER[60](SCI1,RXI1).DTCE
0x8713D ICU
  [0] DTCER[61](SCI1,TXI1).DTCE
0x8713E ICU
  [0] DTCER[62](SCI2,RXI2).DTCE
0x8713F ICU
  [0] DTCER[63](SCI2,TXI2).DTCE
0x87140 ICU
  [0] DTCER[64](ICU,IRQ0).DTCE
0x87141 ICU
  [0] DTCER[65](ICU,IRQ1).DTCE
0x87142 ICU
  [0] DTCER[66](ICU,IRQ2).DTCE
0x87143 ICU
  [0] DTCER[67](ICU,IRQ3).DTCE
0x87144 ICU
  [0] DTCER[68](ICU,IRQ4).DTCE
0x87145 ICU
  [0] DTCER[69](ICU,IRQ5).DTCE
0x87146 ICU
  [0] DTCER[70](ICU,IRQ6).DTCE
0x87147 ICU
  [0] DTCER[71](ICU,IRQ7).DTCE
0x87148 ICU
  [0] DTCER[72](ICU,IRQ8).DTCE
0x87149 ICU
  [0] DTCER[73](ICU,IRQ9).DTCE
0x8714A ICU
  [0] DTCER[74](ICU,IRQ10).DTCE
0x8714B ICU
  [0] DTCER[75](ICU,IRQ11).DTCE
0x8714C ICU
  [0] DTCER[76](ICU,IRQ12).DTCE
0x8714D ICU
  [0] DTCER[77](ICU,IRQ13).DTCE
0x8714E ICU
  [0] DTCER[78](ICU,IRQ14).DTCE
0x8714F ICU
  [0] DTCER[79](ICU,IRQ15).DTCE
0x87150 ICU
  [0] DTCER[80](SCI3,RXI3).DTCE
0x87151 ICU
  [0] DTCER[81](SCI3,TXI3).DTCE
0x87152 ICU
  [0] DTCER[82](SCI4,RXI4).DTCE
0x87153 ICU
  [0] DTCER[83](SCI4,TXI4).DTCE
0x87154 ICU
  [0] DTCER[84](SCI5,RXI5).DTCE
0x87155 ICU
  [0] DTCER[85](SCI5,TXI5).DTCE
0x87156 ICU
  [0] DTCER[86](SCI6,RXI6).DTCE
0x87157 ICU
  [0] DTCER[87](SCI6,TXI6).DTCE
0x87158 ICU
  [0] DTCER[88](LVD1,LVD1).DTCE
0x87159 ICU
  [0] DTCER[89](LVD2,LVD2).DTCE
0x8715A ICU
  [0] DTCER[90](USB0,USBR0).DTCE
0x8715B ICU
  [0] DTCER[91].DTCE
0x8715C ICU
  [0] DTCER[92](RTC,ALM).DTCE
0x8715D ICU
  [0] DTCER[93](RTC,PRD).DTCE
0x8715E ICU
  [0] DTCER[94].DTCE
0x8715F ICU
  [0] DTCER[95](IWDT,IWUNI).DTCE
0x87160 ICU
  [0] DTCER[96](WDT,WUNI).DTCE
0x87161 ICU
  [0] DTCER[97](PDC,PCDFI).DTCE
0x87162 ICU
  [0] DTCER[98](SCI7,RXI7).DTCE
0x87163 ICU
  [0] DTCER[99](SCI7,TXI7).DTCE
0x87164 ICU
  [0] DTCER[100](SCI8,RXI8).DTCE
0x87165 ICU
  [0] DTCER[101](SCI8,TXI8).DTCE
0x87166 ICU
  [0] DTCER[102](SCI9,RXI9).DTCE
0x87167 ICU
  [0] DTCER[103](SCI9,TXI9).DTCE
0x87168 ICU
  [0] DTCER[104](SCI10,RXI10).DTCE
0x87169 ICU
  [0] DTCER[105](SCI10,TXI10).DTCE
0x8716A ICU
  [0] DTCER[106](ICU,GROUPBE0).DTCE
0x8716B ICU
  [0] DTCER[107](ICU,GROUPBL2).DTCE
0x8716C ICU
  [0] DTCER[108](RSPI2,SPRI2).DTCE
0x8716D ICU
  [0] DTCER[109](RSPI2,SPTI2).DTCE
0x8716E ICU
  [0] DTCER[110](ICU,GROUPBL0).DTCE
0x8716F ICU
  [0] DTCER[111](ICU,GROUPBL1).DTCE
0x87170 ICU
  [0] DTCER[112](ICU,GROUPAL0).DTCE
0x87171 ICU
  [0] DTCER[113](ICU,GROUPAL1).DTCE
0x87172 ICU
  [0] DTCER[114](SCI11,RXI11).DTCE
0x87173 ICU
  [0] DTCER[115](SCI11,TXI11).DTCE
0x87174 ICU
  [0] DTCER[116](SCI12,RXI12).DTCE
0x87175 ICU
  [0] DTCER[117](SCI12,TXI12).DTCE
0x87176 ICU
  [0] DTCER[118].DTCE
0x87177 ICU
  [0] DTCER[119].DTCE
0x87178 ICU
  [0] DTCER[120](DMAC,DMAC0I).DTCE
0x87179 ICU
  [0] DTCER[121](DMAC,DMAC1I).DTCE
0x8717A ICU
  [0] DTCER[122](DMAC,DMAC2I).DTCE
0x8717B ICU
  [0] DTCER[123](DMAC,DMAC3I).DTCE
0x8717C ICU
  [0] DTCER[124](DMAC,DMAC74I).DTCE
0x8717D ICU
  [0] DTCER[125](OST,OSTDI).DTCE
0x8717E ICU
  [0] DTCER[126](EXDMAC,EXDMAC0I).DTCE
0x8717F ICU
  [0] DTCER[127](EXDMAC,EXDMAC1I).DTCE
0x87180 ICU
  [0] DTCER[128](PERIB,INTB128).DTCE
0x87181 ICU
  [0] DTCER[129](PERIB,INTB129).DTCE
0x87182 ICU
  [0] DTCER[130](PERIB,INTB130).DTCE
0x87183 ICU
  [0] DTCER[131](PERIB,INTB131).DTCE
0x87184 ICU
  [0] DTCER[132](PERIB,INTB132).DTCE
0x87185 ICU
  [0] DTCER[133](PERIB,INTB133).DTCE
0x87186 ICU
  [0] DTCER[134](PERIB,INTB134).DTCE
0x87187 ICU
  [0] DTCER[135](PERIB,INTB135).DTCE
0x87188 ICU
  [0] DTCER[136](PERIB,INTB136).DTCE
0x87189 ICU
  [0] DTCER[137](PERIB,INTB137).DTCE
0x8718A ICU
  [0] DTCER[138](PERIB,INTB138).DTCE
0x8718B ICU
  [0] DTCER[139](PERIB,INTB139).DTCE
0x8718C ICU
  [0] DTCER[140](PERIB,INTB140).DTCE
0x8718D ICU
  [0] DTCER[141](PERIB,INTB141).DTCE
0x8718E ICU
  [0] DTCER[142](PERIB,INTB142).DTCE
0x8718F ICU
  [0] DTCER[143](PERIB,INTB143).DTCE
0x87190 ICU
  [0] DTCER[144](PERIB,INTB144).DTCE
0x87191 ICU
  [0] DTCER[145](PERIB,INTB145).DTCE
0x87192 ICU
  [0] DTCER[146](PERIB,INTB146).DTCE
0x87193 ICU
  [0] DTCER[147](PERIB,INTB147).DTCE
0x87194 ICU
  [0] DTCER[148](PERIB,INTB148).DTCE
0x87195 ICU
  [0] DTCER[149](PERIB,INTB149).DTCE
0x87196 ICU
  [0] DTCER[150](PERIB,INTB150).DTCE
0x87197 ICU
  [0] DTCER[151](PERIB,INTB151).DTCE
0x87198 ICU
  [0] DTCER[152](PERIB,INTB152).DTCE
0x87199 ICU
  [0] DTCER[153](PERIB,INTB153).DTCE
0x8719A ICU
  [0] DTCER[154](PERIB,INTB154).DTCE
0x8719B ICU
  [0] DTCER[155](PERIB,INTB155).DTCE
0x8719C ICU
  [0] DTCER[156](PERIB,INTB156).DTCE
0x8719D ICU
  [0] DTCER[157](PERIB,INTB157).DTCE
0x8719E ICU
  [0] DTCER[158](PERIB,INTB158).DTCE
0x8719F ICU
  [0] DTCER[159](PERIB,INTB159).DTCE
0x871A0 ICU
  [0] DTCER[160](PERIB,INTB160).DTCE
0x871A1 ICU
  [0] DTCER[161](PERIB,INTB161).DTCE
0x871A2 ICU
  [0] DTCER[162](PERIB,INTB162).DTCE
0x871A3 ICU
  [0] DTCER[163](PERIB,INTB163).DTCE
0x871A4 ICU
  [0] DTCER[164](PERIB,INTB164).DTCE
0x871A5 ICU
  [0] DTCER[165](PERIB,INTB165).DTCE
0x871A6 ICU
  [0] DTCER[166](PERIB,INTB166).DTCE
0x871A7 ICU
  [0] DTCER[167](PERIB,INTB167).DTCE
0x871A8 ICU
  [0] DTCER[168](PERIB,INTB168).DTCE
0x871A9 ICU
  [0] DTCER[169](PERIB,INTB169).DTCE
0x871AA ICU
  [0] DTCER[170](PERIB,INTB170).DTCE
0x871AB ICU
  [0] DTCER[171](PERIB,INTB171).DTCE
0x871AC ICU
  [0] DTCER[172](PERIB,INTB172).DTCE
0x871AD ICU
  [0] DTCER[173](PERIB,INTB173).DTCE
0x871AE ICU
  [0] DTCER[174](PERIB,INTB174).DTCE
0x871AF ICU
  [0] DTCER[175](PERIB,INTB175).DTCE
0x871B0 ICU
  [0] DTCER[176](PERIB,INTB176).DTCE
0x871B1 ICU
  [0] DTCER[177](PERIB,INTB177).DTCE
0x871B2 ICU
  [0] DTCER[178](PERIB,INTB178).DTCE
0x871B3 ICU
  [0] DTCER[179](PERIB,INTB179).DTCE
0x871B4 ICU
  [0] DTCER[180](PERIB,INTB180).DTCE
0x871B5 ICU
  [0] DTCER[181](PERIB,INTB181).DTCE
0x871B6 ICU
  [0] DTCER[182](PERIB,INTB182).DTCE
0x871B7 ICU
  [0] DTCER[183](PERIB,INTB183).DTCE
0x871B8 ICU
  [0] DTCER[184](PERIB,INTB184).DTCE
0x871B9 ICU
  [0] DTCER[185](PERIB,INTB185).DTCE
0x871BA ICU
  [0] DTCER[186](PERIB,INTB186).DTCE
0x871BB ICU
  [0] DTCER[187](PERIB,INTB187).DTCE
0x871BC ICU
  [0] DTCER[188](PERIB,INTB188).DTCE
0x871BD ICU
  [0] DTCER[189](PERIB,INTB189).DTCE
0x871BE ICU
  [0] DTCER[190](PERIB,INTB190).DTCE
0x871BF ICU
  [0] DTCER[191](PERIB,INTB191).DTCE
0x871C0 ICU
  [0] DTCER[192](PERIB,INTB192).DTCE
0x871C1 ICU
  [0] DTCER[193](PERIB,INTB193).DTCE
0x871C2 ICU
  [0] DTCER[194](PERIB,INTB194).DTCE
0x871C3 ICU
  [0] DTCER[195](PERIB,INTB195).DTCE
0x871C4 ICU
  [0] DTCER[196](PERIB,INTB196).DTCE
0x871C5 ICU
  [0] DTCER[197](PERIB,INTB197).DTCE
0x871C6 ICU
  [0] DTCER[198](PERIB,INTB198).DTCE
0x871C7 ICU
  [0] DTCER[199](PERIB,INTB199).DTCE
0x871C8 ICU
  [0] DTCER[200](PERIB,INTB200).DTCE
0x871C9 ICU
  [0] DTCER[201](PERIB,INTB201).DTCE
0x871CA ICU
  [0] DTCER[202](PERIB,INTB202).DTCE
0x871CB ICU
  [0] DTCER[203](PERIB,INTB203).DTCE
0x871CC ICU
  [0] DTCER[204](PERIB,INTB204).DTCE
0x871CD ICU
  [0] DTCER[205](PERIB,INTB205).DTCE
0x871CE ICU
  [0] DTCER[206](PERIB,INTB206).DTCE
0x871CF ICU
  [0] DTCER[207](PERIB,INTB207).DTCE
0x871D0 ICU
  [0] DTCER[208](PERIA,INTA208).DTCE
0x871D1 ICU
  [0] DTCER[209](PERIA,INTA209).DTCE
0x871D2 ICU
  [0] DTCER[210](PERIA,INTA210).DTCE
0x871D3 ICU
  [0] DTCER[211](PERIA,INTA211).DTCE
0x871D4 ICU
  [0] DTCER[212](PERIA,INTA212).DTCE
0x871D5 ICU
  [0] DTCER[213](PERIA,INTA213).DTCE
0x871D6 ICU
  [0] DTCER[214](PERIA,INTA214).DTCE
0x871D7 ICU
  [0] DTCER[215](PERIA,INTA215).DTCE
0x871D8 ICU
  [0] DTCER[216](PERIA,INTA216).DTCE
0x871D9 ICU
  [0] DTCER[217](PERIA,INTA217).DTCE
0x871DA ICU
  [0] DTCER[218](PERIA,INTA218).DTCE
0x871DB ICU
  [0] DTCER[219](PERIA,INTA219).DTCE
0x871DC ICU
  [0] DTCER[220](PERIA,INTA220).DTCE
0x871DD ICU
  [0] DTCER[221](PERIA,INTA221).DTCE
0x871DE ICU
  [0] DTCER[222](PERIA,INTA222).DTCE
0x871DF ICU
  [0] DTCER[223](PERIA,INTA223).DTCE
0x871E0 ICU
  [0] DTCER[224](PERIA,INTA224).DTCE
0x871E1 ICU
  [0] DTCER[225](PERIA,INTA225).DTCE
0x871E2 ICU
  [0] DTCER[226](PERIA,INTA226).DTCE
0x871E3 ICU
  [0] DTCER[227](PERIA,INTA227).DTCE
0x871E4 ICU
  [0] DTCER[228](PERIA,INTA228).DTCE
0x871E5 ICU
  [0] DTCER[229](PERIA,INTA229).DTCE
0x871E6 ICU
  [0] DTCER[230](PERIA,INTA230).DTCE
0x871E7 ICU
  [0] DTCER[231](PERIA,INTA231).DTCE
0x871E8 ICU
  [0] DTCER[232](PERIA,INTA232).DTCE
0x871E9 ICU
  [0] DTCER[233](PERIA,INTA233).DTCE
0x871EA ICU
  [0] DTCER[234](PERIA,INTA234).DTCE
0x871EB ICU
  [0] DTCER[235](PERIA,INTA235).DTCE
0x871EC ICU
  [0] DTCER[236](PERIA,INTA236).DTCE
0x871ED ICU
  [0] DTCER[237](PERIA,INTA237).DTCE
0x871EE ICU
  [0] DTCER[238](PERIA,INTA238).DTCE
0x871EF ICU
  [0] DTCER[239](PERIA,INTA239).DTCE
0x871F0 ICU
  [0] DTCER[240](PERIA,INTA240).DTCE
0x871F1 ICU
  [0] DTCER[241](PERIA,INTA241).DTCE
0x871F2 ICU
  [0] DTCER[242](PERIA,INTA242).DTCE
0x871F3 ICU
  [0] DTCER[243](PERIA,INTA243).DTCE
0x871F4 ICU
  [0] DTCER[244](PERIA,INTA244).DTCE
0x871F5 ICU
  [0] DTCER[245](PERIA,INTA245).DTCE
0x871F6 ICU
  [0] DTCER[246](PERIA,INTA246).DTCE
0x871F7 ICU
  [0] DTCER[247](PERIA,INTA247).DTCE
0x871F8 ICU
  [0] DTCER[248](PERIA,INTA248).DTCE
0x871F9 ICU
  [0] DTCER[249](PERIA,INTA249).DTCE
0x871FA ICU
  [0] DTCER[250](PERIA,INTA250).DTCE
0x871FB ICU
  [0] DTCER[251](PERIA,INTA251).DTCE
0x871FC ICU
  [0] DTCER[252](PERIA,INTA252).DTCE
0x871FD ICU
  [0] DTCER[253](PERIA,INTA253).DTCE
0x871FE ICU
  [0] DTCER[254](PERIA,INTA254).DTCE
0x871FF ICU
  [0] DTCER[255](PERIA,INTA255).DTCE
0x87200 ICU
  [n] IER00.IEN{n} (n=0..7)
0x87201 ICU
  [n] IER01.IEN{n} (n=0..7)
0x87202 ICU
  [7] IER02.IEN7(FCU,FRDYI), [6] IER02.IEN6, [5] IER02.IEN5(FCU,FIFERR), [4] IER02.IEN4, [3] IER02.IEN3, [2] IER02.IEN2(RAM,RAMERR), [1] IER02.IEN1, [0] IER02.IEN0(BSC,BUSERR)
0x87203 ICU
  [7] IER03.IEN7(CMTW1,CMWI1), [6] IER03.IEN6(CMTW0,CMWI0), [5] IER03.IEN5(CMT1,CMI1), [4] IER03.IEN4(CMT0,CMI0), [3] IER03.IEN3(ICU,SWINT), [2] IER03.IEN2(ICU,SWINT2), [1] IER03.IEN1, [0] IER03.IEN0
0x87204 ICU
  [7] IER04.IEN7(RSPI0,SPTI0), [6] IER04.IEN6(RSPI0,SPRI0), [5] IER04.IEN5, [4] IER04.IEN4, [3] IER04.IEN3(USB0,D1FIFO0), [2] IER04.IEN2(USB0,D0FIFO0), [1] IER04.IEN1, [0] IER04.IEN0
0x87205 ICU
  [7] IER05.IEN7, [6] IER05.IEN6, [5] IER05.IEN5(MMCIF,MBFAI), [4] IER05.IEN4(SDHI,SBFAI), [3] IER05.IEN3(QSPI,SPTI), [2] IER05.IEN2(QSPI,SPRI), [1] IER05.IEN1(RSPI1,SPTI1), [0] IER05.IEN0(RSPI1,SPRI1)
0x87206 ICU
  [7] IER06.IEN7(RIIC2,TXI2), [6] IER06.IEN6(RIIC2,RXI2), [5] IER06.IEN5(RIIC0,TXI0), [4] IER06.IEN4(RIIC0,RXI0), [3] IER06.IEN3(RIIC1,TXI1), [2] IER06.IEN2(RIIC1,RXI1), [1] IER06.IEN1, [0] IER06.IEN0
0x87207 ICU
  [7] IER07.IEN7(SCI2,TXI2), [6] IER07.IEN6(SCI2,RXI2), [5] IER07.IEN5(SCI1,TXI1), [4] IER07.IEN4(SCI1,RXI1), [3] IER07.IEN3(SCI0,TXI0), [2] IER07.IEN2(SCI0,RXI0), [1] IER07.IEN1, [0] IER07.IEN0
0x87208 ICU
  [n] IER08.IEN{n}(ICU,IRQ{n}) (n=0..7)
0x87209 ICU
  [n] IER09.IEN{n}(ICU,IRQ{n+8}) (n=0..7)
0x8720A ICU
  [2n-5] IER0A.IEN{2n-5}(SCI{n},TXI{n}) (n=3..6), [2n-6] IER0A.IEN{2n-6}(SCI{n},RXI{n}) (n=3..6)
0x8720B ICU
  [7] IER0B.IEN7(IWDT,IWUNI), [6] IER0B.IEN6, [5] IER0B.IEN5(RTC,PRD), [4] IER0B.IEN4(RTC,ALM), [3] IER0B.IEN3, [2] IER0B.IEN2(USB0,USBR0), [1] IER0B.IEN1(LVD2,LVD2), [0] IER0B.IEN0(LVD1,LVD1)
0x8720C ICU
  [7] IER0C.IEN7(SCI9,TXI9), [6] IER0C.IEN6(SCI9,RXI9), [5] IER0C.IEN5(SCI8,TXI8), [4] IER0C.IEN4(SCI8,RXI8), [3] IER0C.IEN3(SCI7,TXI7), [2] IER0C.IEN2(SCI7,RXI7), [1] IER0C.IEN1(PDC,PCDFI), [0] IER0C.IEN0(WDT,WUNI)
0x8720D ICU
  [7] IER0D.IEN7(ICU,GROUPBL1), [6] IER0D.IEN6(ICU,GROUPBL0), [5] IER0D.IEN5(RSPI2,SPTI2), [4] IER0D.IEN4(RSPI2,SPRI2), [3] IER0D.IEN3(ICU,GROUPBL2), [2] IER0D.IEN2(ICU,GROUPBE0), [1] IER0D.IEN1(SCI10,TXI10), [0] IER0D.IEN0(SCI10,RXI10)
0x8720E ICU
  [7] IER0E.IEN7, [6] IER0E.IEN6, [5] IER0E.IEN5(SCI12,TXI12), [4] IER0E.IEN4(SCI12,RXI12), [3] IER0E.IEN3(SCI11,TXI11), [2] IER0E.IEN2(SCI11,RXI11), [1] IER0E.IEN1(ICU,GROUPAL1), [0] IER0E.IEN0(ICU,GROUPAL0)
0x8720F ICU
  [7] IER0F.IEN7(EXDMAC,EXDMAC1I), [6] IER0F.IEN6(EXDMAC,EXDMAC0I), [5] IER0F.IEN5(OST,OSTDI), [4] IER0F.IEN4(DMAC,DMAC74I), [n] IER0F.IEN{n}(DMAC,DMAC{n}I) (n=0..3)
0x87210 ICU
  [n] IER10.IEN{n}(PERIB,INTB{n+128}) (n=0..7)
0x87211 ICU
  [n] IER11.IEN{n}(PERIB,INTB{n+136}) (n=0..7)
0x87212 ICU
  [n] IER12.IEN{n}(PERIB,INTB{n+144}) (n=0..7)
0x87213 ICU
  [n] IER13.IEN{n}(PERIB,INTB{n+152}) (n=0..7)
0x87214 ICU
  [n] IER14.IEN{n}(PERIB,INTB{n+160}) (n=0..7)
0x87215 ICU
  [n] IER15.IEN{n}(PERIB,INTB{n+168}) (n=0..7)
0x87216 ICU
  [n] IER16.IEN{n}(PERIB,INTB{n+176}) (n=0..7)
0x87217 ICU
  [n] IER17.IEN{n}(PERIB,INTB{n+184}) (n=0..7)
0x87218 ICU
  [n] IER18.IEN{n}(PERIB,INTB{n+192}) (n=0..7)
0x87219 ICU
  [n] IER19.IEN{n}(PERIB,INTB{n+200}) (n=0..7)
0x8721A ICU
  [n] IER1A.IEN{n}(PERIA,INTA{n+208}) (n=0..7)
0x8721B ICU
  [n] IER1B.IEN{n}(PERIA,INTA{n+216}) (n=0..7)
0x8721C ICU
  [n] IER1C.IEN{n}(PERIA,INTA{n+224}) (n=0..7)
0x8721D ICU
  [n] IER1D.IEN{n}(PERIA,INTA{n+232}) (n=0..7)
0x8721E ICU
  [n] IER1E.IEN{n}(PERIA,INTA{n+240}) (n=0..7)
0x8721F ICU
  [n] IER1F.IEN{n}(PERIA,INTA{n+248}) (n=0..7)
0x872E0 ICU
  [0] SWINTR.SWINT
0x872E1 ICU
  [0] SWINT2R.SWINT2
0x872F0 ICU 16-bit
  [15] FIR.FIEN, [7:0] FIR.FVCT
0x87300 ICU
  [3:0] IPR[0](BSC,BUSERR...).IPR
0x87301 ICU
  [3:0] IPR[1](FCU,FIFERR).IPR
0x87302 ICU
  [3:0] IPR[2](FCU,FRDYI).IPR
0x87303 ICU
  [3:0] IPR[3](ICU,SWINT2...).IPR
0x87304 ICU
  [3:0] IPR[4](CMT0,CMI0).IPR
0x87305 ICU
  [3:0] IPR[5](CMT1,CMI1).IPR
0x87306 ICU
  [3:0] IPR[6](CMTW0,CMWI0).IPR
0x87307 ICU
  [3:0] IPR[7](CMTW1,CMWI1).IPR
0x87308 ICU
  [3:0] IPR[8].IPR
0x87309 ICU
  [3:0] IPR[9].IPR
0x8730A ICU
  [3:0] IPR[10].IPR
0x8730B ICU
  [3:0] IPR[11].IPR
0x8730C ICU
  [3:0] IPR[12].IPR
0x8730D ICU
  [3:0] IPR[13].IPR
0x8730E ICU
  [3:0] IPR[14].IPR
0x8730F ICU
  [3:0] IPR[15].IPR
0x87310 ICU
  [3:0] IPR[16].IPR
0x87311 ICU
  [3:0] IPR[17].IPR
0x87312 ICU
  [3:0] IPR[18].IPR
0x87313 ICU
  [3:0] IPR[19].IPR
0x87314 ICU
  [3:0] IPR[20].IPR
0x87315 ICU
  [3:0] IPR[21].IPR
0x87316 ICU
  [3:0] IPR[22].IPR
0x87317 ICU
  [3:0] IPR[23].IPR
0x87318 ICU
  [3:0] IPR[24].IPR
0x87319 ICU
  [3:0] IPR[25].IPR
0x8731A ICU
  [3:0] IPR[26].IPR
0x8731B ICU
  [3:0] IPR[27].IPR
0x8731C ICU
  [3:0] IPR[28].IPR
0x8731D ICU
  [3:0] IPR[29].IPR
0x8731E ICU
  [3:0] IPR[30].IPR
0x8731F ICU
  [3:0] IPR[31].IPR
0x87320 ICU
  [3:0] IPR[32].IPR
0x87321 ICU
  [3:0] IPR[33].IPR
0x87322 ICU
  [3:0] IPR[34](USB0,D0FIFO0).IPR
0x87323 ICU
  [3:0] IPR[35](USB0,D1FIFO0).IPR
0x87324 ICU
  [3:0] IPR[36].IPR
0x87325 ICU
  [3:0] IPR[37].IPR
0x87326 ICU
  [3:0] IPR[38](RSPI0,SPRI0).IPR
0x87327 ICU
  [3:0] IPR[39](RSPI0,SPTI0).IPR
0x87328 ICU
  [3:0] IPR[40](RSPI1,SPRI1).IPR
0x87329 ICU
  [3:0] IPR[41](RSPI1,SPTI1).IPR
0x8732A ICU
  [3:0] IPR[42](QSPI,SPRI).IPR
0x8732B ICU
  [3:0] IPR[43](QSPI,SPTI).IPR
0x8732C ICU
  [3:0] IPR[44](SDHI,SBFAI).IPR
0x8732D ICU
  [3:0] IPR[45](MMCIF,MBFAI).IPR
0x8732E ICU
  [3:0] IPR[46].IPR
0x8732F ICU
  [3:0] IPR[47].IPR
0x87330 ICU
  [3:0] IPR[48].IPR
0x87331 ICU
  [3:0] IPR[49].IPR
0x87332 ICU
  [3:0] IPR[50](RIIC1,RXI1).IPR
0x87333 ICU
  [3:0] IPR[51](RIIC1,TXI1).IPR
0x87334 ICU
  [3:0] IPR[52](RIIC0,RXI0).IPR
0x87335 ICU
  [3:0] IPR[53](RIIC0,TXI0).IPR
0x87336 ICU
  [3:0] IPR[54](RIIC2,RXI2).IPR
0x87337 ICU
  [3:0] IPR[55](RIIC2,TXI2).IPR
0x87338 ICU
  [3:0] IPR[56].IPR
0x87339 ICU
  [3:0] IPR[57].IPR
0x8733A ICU
  [3:0] IPR[58](SCI0,RXI0).IPR
0x8733B ICU
  [3:0] IPR[59](SCI0,TXI0).IPR
0x8733C ICU
  [3:0] IPR[60](SCI1,RXI1).IPR
0x8733D ICU
  [3:0] IPR[61](SCI1,TXI1).IPR
0x8733E ICU
  [3:0] IPR[62](SCI2,RXI2).IPR
0x8733F ICU
  [3:0] IPR[63](SCI2,TXI2).IPR
0x87340 ICU
  [3:0] IPR[64](ICU,IRQ0).IPR
0x87341 ICU
  [3:0] IPR[65](ICU,IRQ1).IPR
0x87342 ICU
  [3:0] IPR[66](ICU,IRQ2).IPR
0x87343 ICU
  [3:0] IPR[67](ICU,IRQ3).IPR
0x87344 ICU
  [3:0] IPR[68](ICU,IRQ4).IPR
0x87345 ICU
  [3:0] IPR[69](ICU,IRQ5).IPR
0x87346 ICU
  [3:0] IPR[70](ICU,IRQ6).IPR
0x87347 ICU
  [3:0] IPR[71](ICU,IRQ7).IPR
